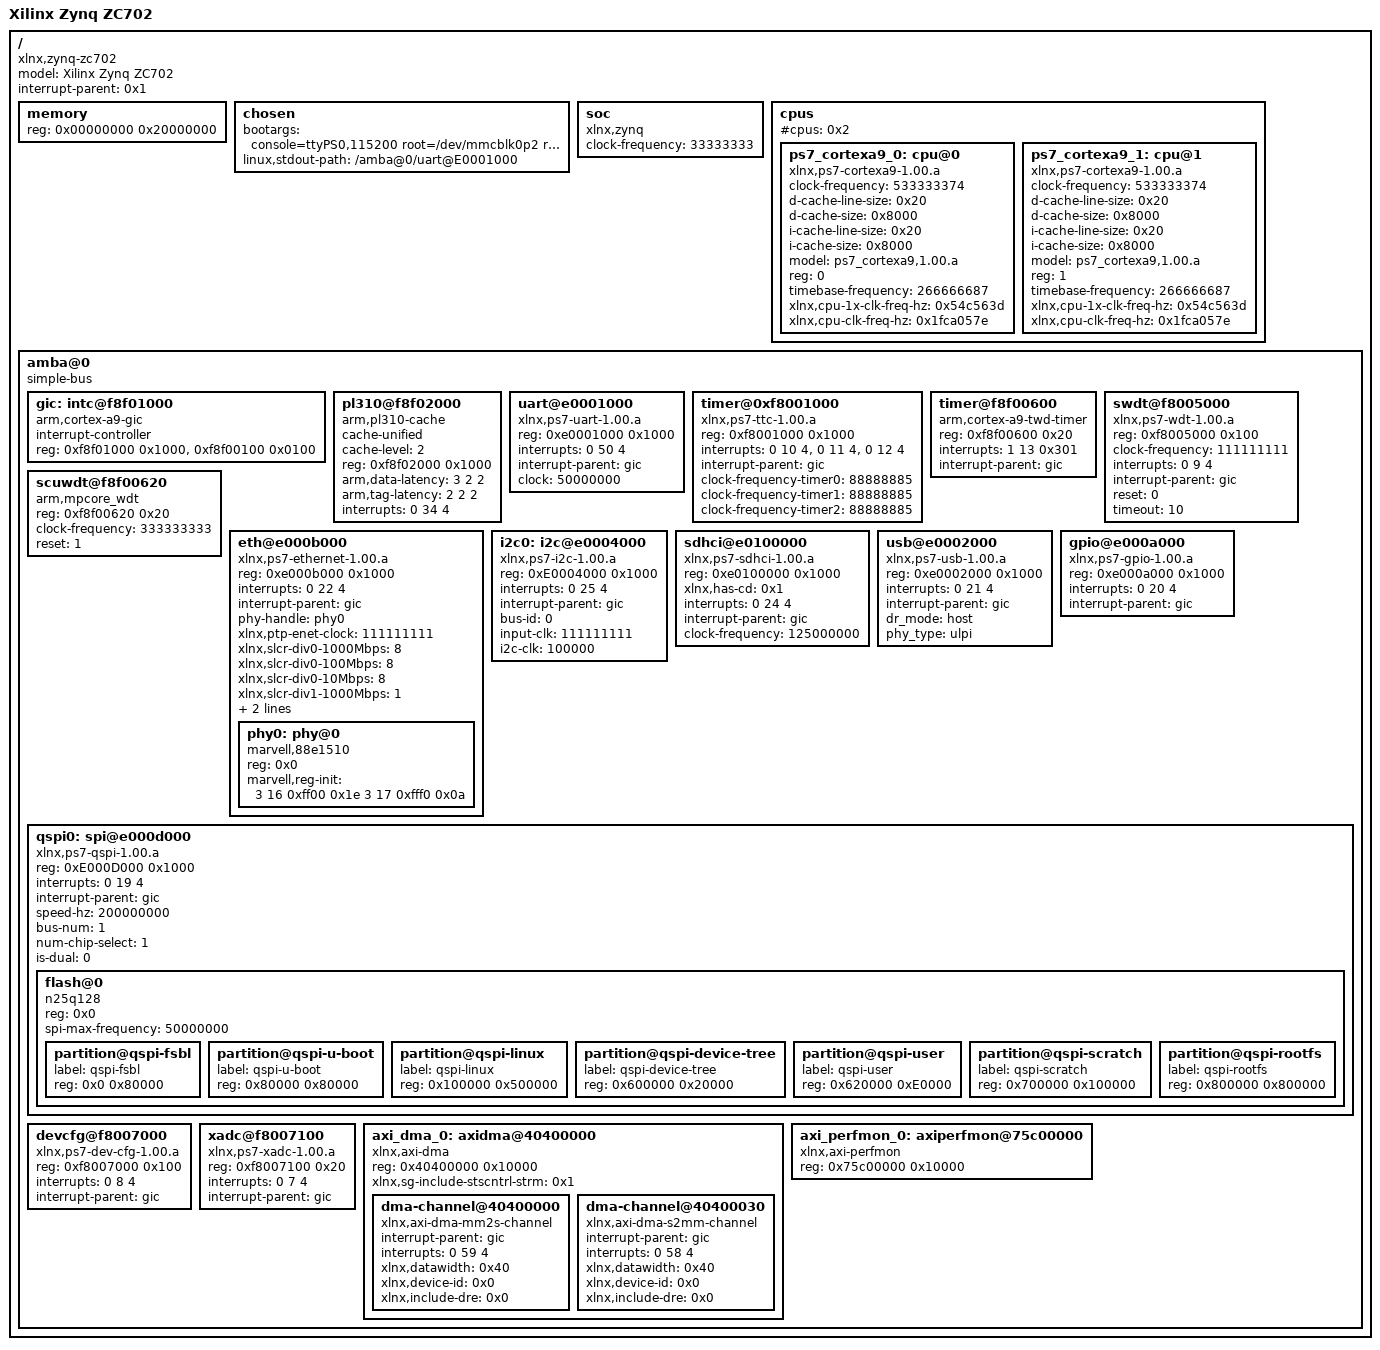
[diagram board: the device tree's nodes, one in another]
/dts-v1/;

/ {
	model = "Xilinx Zynq ZC702";
	compatible = "xlnx,zynq-zc702";
	#address-cells = <0x1>;
	#size-cells = <0x1>;
	interrupt-parent = <0x1>;

	memory {
		device_type = "memory";
		reg = <0x00000000 0x20000000>; 
	};
	chosen {
		bootargs = "console=ttyPS0,115200 root=/dev/mmcblk0p2 rw earlyprintk rootfstype=ext4 loglevel=8 rootwait profile=2"; 
		//rootdelay=20 
		linux,stdout-path = "/amba@0/uart@E0001000";
	};

	soc {
		compatible = "xlnx,zynq";
		clock-frequency = <33333333>;
	};

	cpus {
		#address-cells = <1>;
		#cpus = <0x2>;
		#size-cells = <0>;
		ps7_cortexa9_0: cpu@0 {
			clock-frequency = <533333374>;
			compatible = "xlnx,ps7-cortexa9-1.00.a";
			d-cache-line-size = <0x20>;
			d-cache-size = <0x8000>;
			device_type = "cpu";
			i-cache-line-size = <0x20>;
			i-cache-size = <0x8000>;
			model = "ps7_cortexa9,1.00.a";
			reg = <0>;
			timebase-frequency = <266666687>;
			xlnx,cpu-1x-clk-freq-hz = <0x54c563d>;
			xlnx,cpu-clk-freq-hz = <0x1fca057e>;
		} ;
		ps7_cortexa9_1: cpu@1 {
			clock-frequency = <533333374>;
			compatible = "xlnx,ps7-cortexa9-1.00.a";
			d-cache-line-size = <0x20>;
			d-cache-size = <0x8000>;
			device_type = "cpu";
			i-cache-line-size = <0x20>;
			i-cache-size = <0x8000>;
			model = "ps7_cortexa9,1.00.a";
			reg = <1>;
			timebase-frequency = <266666687>;
			xlnx,cpu-1x-clk-freq-hz = <0x54c563d>;
			xlnx,cpu-clk-freq-hz = <0x1fca057e>;
		};
	};


	amba@0 {
		compatible = "simple-bus";
		#address-cells = <0x1>;
		#size-cells = <0x1>;
		ranges;

		gic: intc@f8f01000 {
			interrupt-controller;
			compatible = "arm,cortex-a9-gic";
			#interrupt-cells = <3>;
			reg = < 0xf8f01000 0x1000 >,
			      < 0xf8f00100 0x0100 >;
		};

		pl310@f8f02000 {
			compatible = "arm,pl310-cache";
			cache-unified;
			cache-level = <2>;
			reg = <0xf8f02000 0x1000>;
			arm,data-latency = <3 2 2>;
			arm,tag-latency = <2 2 2>;
			interrupts = <0 34 4>;
		};

		uart@e0001000 {
			compatible = "xlnx,ps7-uart-1.00.a";
			reg = <0xe0001000 0x1000>;
			interrupts = < 0 50 4 >;
			interrupt-parent = <&gic>;
			clock = <50000000>;
		};

		timer@0xf8001000 {
			compatible = "xlnx,ps7-ttc-1.00.a";
			reg = <0xf8001000 0x1000>;
			interrupts = <0 10 4>,<0 11 4>,<0 12 4>; 
			interrupt-parent = <&gic>;
			clock-frequency-timer0 = <88888885>;
			clock-frequency-timer1 = <88888885>;
			clock-frequency-timer2 = <88888885>;
		};

		timer@f8f00600 {
			compatible = "arm,cortex-a9-twd-timer";
			reg = <0xf8f00600 0x20>;
			interrupts = <1 13 0x301>;
			interrupt-parent = <&gic>;
		};

		swdt@f8005000 {
			device_type = "watchdog";
			compatible = "xlnx,ps7-wdt-1.00.a";
			reg = <0xf8005000 0x100>;
			clock-frequency = <111111111>;
			interrupts = <0 9 4>;
			interrupt-parent = <&gic>;
			reset = <0>;
			timeout = <10>;
		};

		scuwdt@f8f00620 {
			device_type = "watchdog";
			compatible = "arm,mpcore_wdt";
			reg = <0xf8f00620 0x20>;
			clock-frequency = <333333333>;
			reset = <1>;
		};

		eth@e000b000 {
			compatible = "xlnx,ps7-ethernet-1.00.a";
			reg = <0xe000b000 0x1000>;
			interrupts = <0 22 4>;
			interrupt-parent = <&gic>;
			phy-handle = <&phy0>;
			xlnx,ptp-enet-clock = <111111111>;
			xlnx,slcr-div0-1000Mbps = <8>;
			xlnx,slcr-div0-100Mbps = <8>;
			xlnx,slcr-div0-10Mbps = <8>;
			xlnx,slcr-div1-1000Mbps = <1>;
			xlnx,slcr-div1-100Mbps = <5>;
			xlnx,slcr-div1-10Mbps = <50>;
			#address-cells = <0x1>;
			#size-cells = <0x0>;

			phy0: phy@0 {
				compatible = "marvell,88e1510";
				device_type = "ethernet-phy";
				reg = <0x0>;
				marvell,reg-init=<3 16 0xff00 0x1e 3 17 0xfff0 0x0a>;
			};
		};

		i2c0: i2c@e0004000 {
			compatible = "xlnx,ps7-i2c-1.00.a";
			reg = <0xE0004000 0x1000>;
			interrupts = <0 25 4>;
			interrupt-parent = <&gic>;
			bus-id = <0>;
			input-clk = <111111111>;
			i2c-clk = <100000>;
			
			#address-cells = <1>;
			#size-cells = <0>;
		};

		sdhci@e0100000 {
			compatible = "xlnx,ps7-sdhci-1.00.a";
			reg = <0xe0100000 0x1000>;
			xlnx,has-cd = <0x1>;
			interrupts = <0 24 4>;
			interrupt-parent = <&gic>;
			clock-frequency = <125000000>;
		};

		usb@e0002000 {
			compatible = "xlnx,ps7-usb-1.00.a";
			reg = <0xe0002000 0x1000>;
			interrupts = <0 21 4>;
			interrupt-parent = <&gic>;
			dr_mode = "host";
			phy_type = "ulpi";
		};

		gpio@e000a000 {
			compatible = "xlnx,ps7-gpio-1.00.a";
			reg = <0xe000a000 0x1000>;
			interrupts = <0 20 4>;
			interrupt-parent = <&gic>;
		};

		qspi0: spi@e000d000 {
			compatible = "xlnx,ps7-qspi-1.00.a";
			reg = <0xE000D000 0x1000>;
			interrupts = <0 19 4>;
			interrupt-parent = <&gic>;
			speed-hz = <200000000>;
			bus-num = <1>;
			num-chip-select = <1>;
			#address-cells = <1>;
			#size-cells = <0>;
			is-dual = <0>;
			flash@0 {
			compatible = "n25q128";
			reg = <0x0>;
			spi-max-frequency = <50000000>;
			#address-cells = <1>;
			#size-cells = <1>;
			partition@qspi-fsbl {
				label = "qspi-fsbl";
				reg = <0x0 0x80000>;
				};
			partition@qspi-u-boot {
				label = "qspi-u-boot";
				reg = <0x80000 0x80000>;
				};
			partition@qspi-linux {
				label = "qspi-linux";
				reg = <0x100000 0x500000>;
				};
			partition@qspi-device-tree {
				label = "qspi-device-tree";
				reg = <0x600000 0x20000>;
				};
			partition@qspi-user {
				label = "qspi-user";
				reg = <0x620000 0xE0000>;
				};
			partition@qspi-scratch {
				label = "qspi-scratch";
				reg = <0x700000 0x100000>;
				};
			partition@qspi-rootfs {
				label = "qspi-rootfs";
				reg = <0x800000 0x800000>;
				};
			};
		};

		devcfg@f8007000 {
			compatible = "xlnx,ps7-dev-cfg-1.00.a";
			reg = <0xf8007000 0x100>;
			interrupts = <0 8 4>;
			interrupt-parent = <&gic>;
		};
		xadc@f8007100 {
			compatible = "xlnx,ps7-xadc-1.00.a";
			reg = <0xf8007100 0x20>;
			interrupts = <0 7 4>;
			interrupt-parent = <&gic>;
		};

		axi_dma_0: axidma@40400000 {
			#address-cells = <1>;
			#size-cells = <1>;
			#dma-cells = <1>;
			compatible = "xlnx,axi-dma";
			ranges = < 0x40400000 0x40400000 0x10000 >;
			reg = < 0x40400000 0x10000 >;
			xlnx,sg-include-stscntrl-strm = <0x1>;
			dma-channel@40400000 {
				compatible = "xlnx,axi-dma-mm2s-channel";
				interrupt-parent = <&gic>;
				interrupts = < 0 59 4 >;
				xlnx,datawidth = <0x40>;
				xlnx,device-id = <0x0>;
				xlnx,include-dre = <0x0>;
			};
			dma-channel@40400030 {
				compatible = "xlnx,axi-dma-s2mm-channel";
				interrupt-parent = <&gic>;
				interrupts = < 0 58 4 >;
				xlnx,datawidth = <0x40>;
				xlnx,device-id = <0x0>;
				xlnx,include-dre = <0x0>;
			};
		};

		axi_perfmon_0: axiperfmon@75c00000 {
			compatible = "xlnx,axi-perfmon";
			reg = <0x75c00000 0x10000>;
		};
	};
};
